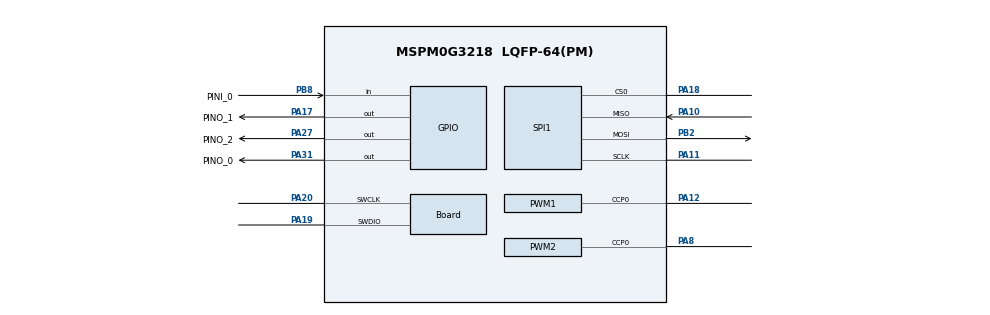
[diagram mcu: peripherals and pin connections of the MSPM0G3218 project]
//@cliArgs --device "MSPM0G321X" --package "LQFP-64(PM)" --part "Default"
//@v2CliArgs --device "MSPM0G3218" --package "LQFP-64(PM)"
// @cliArgs --board /ti/boards/LP_MSPM0G3218 --rtos nortos

/**
 * Import the modules used in this configuration.
 */
const Board         = scripting.addModule("/ti/driverlib/Board");
const GPIO          = scripting.addModule("/ti/driverlib/GPIO", {}, false);
const GPIO1         = GPIO.addInstance();
const GPIO2         = GPIO.addInstance();
const PWM           = scripting.addModule("/ti/driverlib/PWM", {}, false);
const PWM1          = PWM.addInstance();
const PWM2          = PWM.addInstance();
const SPI           = scripting.addModule("/ti/driverlib/SPI", {}, false);
const SPI1          = SPI.addInstance();
const SYSCTL        = scripting.addModule("/ti/driverlib/SYSCTL");
const ProjectConfig = scripting.addModule("/ti/project_config/ProjectConfig");

/**
 * Write custom configuration values to the imported modules.
 */
Board.peripheral.$assign          = "DEBUGSS";
Board.peripheral.swclkPin.$assign = "PA20";
Board.peripheral.swdioPin.$assign = "PA19";

GPIO1.$name                         = "GENERIC_GPIO_IN";
GPIO1.associatedPins[0].$name       = "PINI_0";
GPIO1.associatedPins[0].direction   = "INPUT";
GPIO1.associatedPins[0].pin.$assign = "PB8";

GPIO2.$name                         = "GENERIC_GPIO_OUT";
GPIO2.associatedPins.create(3);
GPIO2.associatedPins[0].$name       = "PINO_0";
GPIO2.associatedPins[0].pin.$assign = "PA31";
GPIO2.associatedPins[1].$name       = "PINO_1";
GPIO2.associatedPins[1].pin.$assign = "PA17";
GPIO2.associatedPins[2].$name       = "PINO_2";
GPIO2.associatedPins[2].pin.$assign = "PA27";

PWM1.ccIndex                            = [0];
PWM1.clockDivider                       = 2;
PWM1.$name                              = "GENERIC_PWM_CHANNEL_0";
PWM1.interrupts                         = ["ZERO_EVENT"];
PWM1.clockPrescale                      = 3;
PWM1.timerCount                         = 53333;
PWM1.interruptPriority                  = "1";
PWM1.PWM_CHANNEL_0.$name                = "ti_driverlib_pwm_PWMTimerCC0";
PWM1.ccp0PinConfig.passedPeripheralType = scripting.forceWrite("Digital");
PWM1.peripheral.$assign                 = "TIMG0";
PWM1.peripheral.ccp0Pin.$assign         = "PA12";

PWM2.$name                              = "GENERIC_PWM_DAC";
PWM2.ccIndex                            = [0];
PWM2.timerStartTimer                    = true;
PWM2.pwmMode                            = "EDGE_ALIGN_UP";
PWM2.timerCount                         = 160;
PWM2.PWM_CHANNEL_0.$name                = "ti_driverlib_pwm_PWMTimerCC1";
PWM2.peripheral.$assign                 = "TIMA0";
PWM2.peripheral.ccp0Pin.$assign         = "PA8";

SPI1.targetBitRate                      = 1000000;
SPI1.phase                              = "1";
SPI1.dataSize                           = 16;
SPI1.rxFifoThreshold                    = "DL_SPI_RX_FIFO_LEVEL_FULL";
SPI1.txFifoThreshold                    = "DL_SPI_TX_FIFO_LEVEL_EMPTY";
SPI1.$name                              = "GENERIC_SPI_CHANNEL_0";
SPI1.peripheral.$assign                 = "UC2";
SPI1.peripheral.sclkPin.$assign         = "PA11";
SPI1.peripheral.mosiPin.$assign         = "PB2";
SPI1.peripheral.misoPin.$assign         = "PA10";
SPI1.peripheral.cs0Pin.$assign          = "PA18";

SYSCTL.MFCLKEn            = true;
SYSCTL.peripheral.$assign = "SYSCTL";

ProjectConfig.genLibIQ = true;
